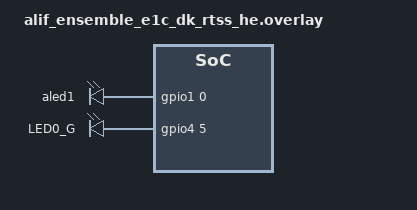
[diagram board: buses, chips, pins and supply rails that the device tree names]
/* Copyright (C) 2025 Alif Semiconductor - All Rights Reserved.
 * Use, distribution and modification of this code is permitted under the
 * terms stated in the Alif Semiconductor Software License Agreement
 *
 * You should have received a copy of the Alif Semiconductor Software
 * License Agreement with this file. If not, please write to:
 * contact@alifsemi.com, or visit: https: //alifsemi.com/license
 *
 */

/{
	aliases {
		led1 = &aled1;
		led0 = &aled0;
	};

	leds {
		aled1: led_1 {
			gpios = <&gpio1 0 0>;
		};
		aled0: led_0 {
			gpios = <&gpio4 5 0>;
			label = "LED0_G";
		};
	};
};

